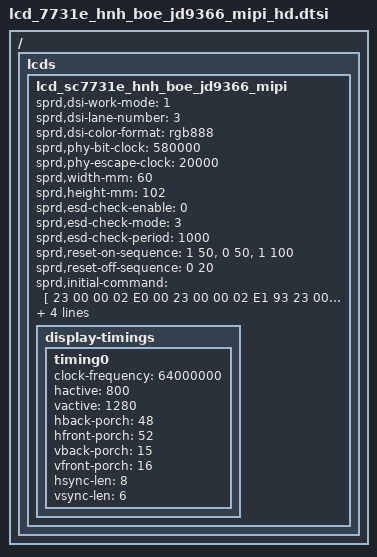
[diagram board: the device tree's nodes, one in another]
/ { lcds {
	lcd_sc7731e_hnh_boe_jd9366_mipi: lcd_sc7731e_hnh_boe_jd9366_mipi {

		sprd,dsi-work-mode = <1>;
		sprd,dsi-lane-number = <3>;
		sprd,dsi-color-format = "rgb888";

		sprd,phy-bit-clock = <580000>;
		sprd,phy-escape-clock = <20000>;

		sprd,width-mm = <60>;
		sprd,height-mm = <102>;

		sprd,esd-check-enable = <0>;
		sprd,esd-check-mode = <3>;
		sprd,esd-check-period = <1000>;
		/*sprd,esd-check-register = <0x0A>;*/
		/*sprd,esd-check-value = <0x9C>;*/

		sprd,reset-on-sequence = <1 50>, <0 50>, <1 100>;
		sprd,reset-off-sequence = <0 20>;

		sprd,initial-command = [
		 23 00 00 02 E0 00 

//--- PASSWORD  ----//
		 23 00 00 02 E1 93 
		 23 00 00 02 E2 65 
		 23 00 00 02 E3 F8 

//Page4
		 23 00 00 02 E0 04 
		 23 00 00 02 1E 69 //SSC
		 23 00 00 02 2B 8B //VCID_CHK=1

		 23 00 00 02 2D 03 
//Page0
		 23 00 00 02 E0 00 

//--- Sequence Ctrl  ----//
		 23 00 00 02 80 02 	//ERR_RPT_EN=0     02  3L


//--- Page1  ----//
		 23 00 00 02 E0 01 

//Set VCOM
		 23 00 00 02 00 00 
		 23 00 00 02 01 9F // B3

//Set VCOM
		 23 00 00 02 03 00 
		 23 00 00 02 04 9F 

//Set Gamma Power  VGMP VGMN VGSP VGSN
		 23 00 00 02 17 00 
		 23 00 00 02 18 B1 
		 23 00 00 02 19 00 
		 23 00 00 02 1A 00 
		 23 00 00 02 1B B1   //VGMN=0
		 23 00 00 02 1C 00 
                
//Set Gate Power
		 23 00 00 02 1F 3E 
		 23 00 00 02 20 2D 	
		 23 00 00 02 21 2D 
		 23 00 00 02 22 0E 

//VDDA_Disable
		 23 00 00 02 24 38   // 38  [7]:VGH_EN=0  [6]:VGL_EN=0
		 23 00 00 02 26 F1 
		 23 00 00 02 27 44 	//SET VDDD


//SET RGBCYC
		 23 00 00 02 37 19 	//[5:4]ENZ[1:0]=10  [3]SS=1  [0]BGR=1
		 23 00 00 02 38 05 	//JDT=101 Zigzag inversion
		 23 00 00 02 39 0C 
		 23 00 00 02 3A 18 


//Set TCON
		 23 00 00 02 40 06 	//RSO=800 Pixels
		 23 00 00 02 41 A0 	//LN=640->1280 line

//--- power voltage  ----//
		 23 00 00 02 55 0F 	//DCDCM=1111  External pwoer ic
		 23 00 00 02 56 01 
		 23 00 00 02 57 69 
		 23 00 00 02 58 0A 
		 23 00 00 02 59 0A 	//VCL = -2.9V
//		 23 00 00 02 5A 28 	//VGH = 19V
//		 23 00 00 02 5B 19 	//VGL = -11V
                
//--- Gamma  ----//
		 23 00 00 02 5D 7C        
		 23 00 00 02 5E 6D        
		 23 00 00 02 5F 61        
		 23 00 00 02 60 55        
		 23 00 00 02 61 53        
		 23 00 00 02 62 44        
		 23 00 00 02 63 48        
		 23 00 00 02 64 31        
		 23 00 00 02 65 49        
		 23 00 00 02 66 47        
		 23 00 00 02 67 47        
		 23 00 00 02 68 65        
		 23 00 00 02 69 50        
		 23 00 00 02 6A 5C        
		 23 00 00 02 6B 4F        
		 23 00 00 02 6C 4F        
		 23 00 00 02 6D 3E        
		 23 00 00 02 6E 36        
		 23 00 00 02 6F 00        
		 23 00 00 02 70 7C        
		 23 00 00 02 71 6D        
		 23 00 00 02 72 61        
		 23 00 00 02 73 55        
		 23 00 00 02 74 53        
		 23 00 00 02 75 44        
		 23 00 00 02 76 48        
		 23 00 00 02 77 31        
		 23 00 00 02 78 49        
		 23 00 00 02 79 47        
		 23 00 00 02 7A 47        
		 23 00 00 02 7B 65        
		 23 00 00 02 7C 50        
		 23 00 00 02 7D 5C        
		 23 00 00 02 7E 4F        
		 23 00 00 02 7F 4F        
		 23 00 00 02 80 3E        
		 23 00 00 02 81 36        
		 23 00 00 02 82 00        


//Page2  for GIP
		 23 00 00 02 E0 02 

//GIP_L Pin mapping
		 23 00 00 02 00 05 
		 23 00 00 02 01 05    
		 23 00 00 02 02 04  
		 23 00 00 02 03 04  
		 23 00 00 02 04 07  
		 23 00 00 02 05 07  
		 23 00 00 02 06 06  
		 23 00 00 02 07 06  
		 23 00 00 02 08 00  
		 23 00 00 02 09 1F  
		 23 00 00 02 0A 1F  
		 23 00 00 02 0B 1F  
		 23 00 00 02 0C 1F  
		 23 00 00 02 0D 1F  
		 23 00 00 02 0E 1F  
		 23 00 00 02 0F 01  
		 23 00 00 02 10 1F  
		 23 00 00 02 11 1F  
		 23 00 00 02 12 1F  
		 23 00 00 02 13 1F  
		 23 00 00 02 14 1F  
		 23 00 00 02 15 1F  

//GIP_R Pin mapping
		 23 00 00 02 16 05 
		 23 00 00 02 17 05    
		 23 00 00 02 18 04  
		 23 00 00 02 19 04  
		 23 00 00 02 1A 07  
		 23 00 00 02 1B 07  
		 23 00 00 02 1C 06  
		 23 00 00 02 1D 06  
		 23 00 00 02 1E 00  
		 23 00 00 02 1F 1F  
		 23 00 00 02 20 1F  
		 23 00 00 02 21 1F  
		 23 00 00 02 22 1F  
		 23 00 00 02 23 1F  
		 23 00 00 02 24 1F  
		 23 00 00 02 25 01  
		 23 00 00 02 26 1F  
		 23 00 00 02 27 1F  
		 23 00 00 02 28 1F  
		 23 00 00 02 29 1F  
		 23 00 00 02 2A 1F  
		 23 00 00 02 2B 1F  

//GIP Timing  
		 23 00 00 02 58 10  
		 23 00 00 02 59 00  
		 23 00 00 02 5A 00  
		 23 00 00 02 5B 10  
		 23 00 00 02 5C 0E  
		 23 00 00 02 5D 20  
		 23 00 00 02 5E 00  
		 23 00 00 02 5F 00  
		 23 00 00 02 60 00  
		 23 00 00 02 61 00  
		 23 00 00 02 62 00  
		 23 00 00 02 63 03  //STV_ON
		 23 00 00 02 64 70  //STV_OFF
		 23 00 00 02 65 00  
		 23 00 00 02 66 00  
		 23 00 00 02 67 31  
		 23 00 00 02 68 10  
		 23 00 00 02 69 06  //CKV_ON
		 23 00 00 02 6A 70  //CKV_OFF
		 23 00 00 02 6B 00  
		 23 00 00 02 6C 00  
		 23 00 00 02 6D 04  
		 23 00 00 02 6E 04  
		 23 00 00 02 6F 88  
		 23 00 00 02 70 00  
		 23 00 00 02 71 00  
		 23 00 00 02 72 06  
		 23 00 00 02 73 7B  
		 23 00 00 02 74 00  
		 23 00 00 02 75 87  
		 23 00 00 02 76 00  
		 23 00 00 02 77 5D  
		 23 00 00 02 78 17  
		 23 00 00 02 79 1F  
		 23 00 00 02 7A 00  
		 23 00 00 02 7B 00  
		 23 00 00 02 7C 00  
		 23 00 00 02 7D 03  
		 23 00 00 02 7E 7B  

//Page3
		 23 00 00 02 E0 03 
		 23 00 00 02 98 3E 	//From 2E to 3E  LED ON

//Page0
		 23 00 00 02 E0 00 
			13 78 00 01 11
			13 64 00 01 29
			];
		sprd,sleep-in-command = [
			13 0A 00 01 28
			13 78 00 01 10
			];
		sprd,sleep-out-command = [
			13 78 00 01 11
			13 64 00 01 29
			];

		display-timings {
			timing0 {
			clock-frequency = <64000000>;
			hactive = <800>;
			vactive = <1280>;
			hback-porch = <48>;
			hfront-porch = <52>;
			vback-porch = <15>;
			vfront-porch = <16>;
			hsync-len = <8>;
			vsync-len = <6>;
			};
		};
	};
};};

